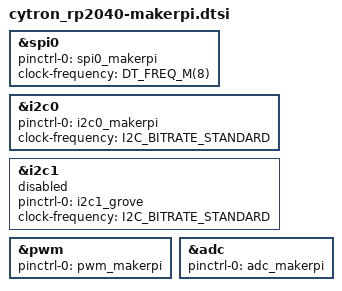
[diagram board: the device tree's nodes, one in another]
/*
 * Copyright (c) 2023 TiaC Systems
 * SPDX-License-Identifier: Apache-2.0
 */

#include <freq.h>
#include <zephyr/dt-bindings/i2c/i2c.h>

#include "cytron_rp2040.dtsi"

&spi0 {
	status = "okay";
	pinctrl-0 = <&spi0_makerpi>;
	pinctrl-names = "default";
	clock-frequency = <DT_FREQ_M(8)>;
};

&i2c0 {
	status = "okay";
	pinctrl-0 = <&i2c0_makerpi>;
	pinctrl-names = "default";
	clock-frequency = <I2C_BITRATE_STANDARD>;
};

&i2c1 {
	status = "disabled";
	pinctrl-0 = <&i2c1_grove>;
	pinctrl-names = "default";
	clock-frequency = <I2C_BITRATE_STANDARD>;
};

&pwm {
	status = "okay";
	pinctrl-0 = <&pwm_makerpi>;
	pinctrl-names = "default";
};

&adc {
	status = "okay";
	pinctrl-0 = <&adc_makerpi>;
	pinctrl-names = "default";
};
